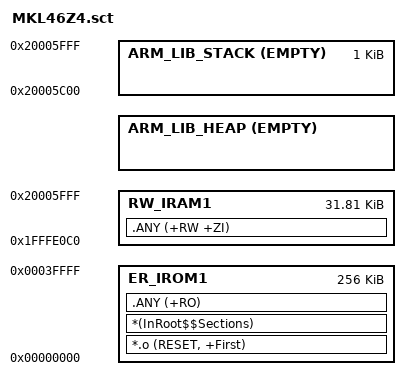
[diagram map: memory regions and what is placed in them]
#! armcc -E

#if !defined(MBED_BOOT_STACK_SIZE)
  #define MBED_BOOT_STACK_SIZE 0x400
#endif

#define Stack_Size MBED_BOOT_STACK_SIZE

LR_IROM1 0x00000000 0x40000  {    ; load region size_region (256k)
  ER_IROM1 0x00000000 0x40000  {  ; load address = execution address
   *.o (RESET, +First)
   *(InRoot$$Sections)
   .ANY (+RO)
  }
  ; 8_byte_aligned(48 vect * 4 bytes) =  8_byte_aligned(0xC0) = 0xC0
  ; 0x8000 - 0xC0 = 0x7F40
  RW_IRAM1 0x1FFFE0C0 0x7F40  {
   .ANY (+RW +ZI)
  }
  
  ARM_LIB_HEAP AlignExpr(+0, 16) EMPTY (0x1FFFE000+0x8000-Stack_Size-AlignExpr(ImageLimit(RW_IRAM1), 16)) { ; Heap region growing up
  }

  ARM_LIB_STACK 0x1FFFE000+0x8000 EMPTY -Stack_Size { ; Stack region growing down
  }
}

